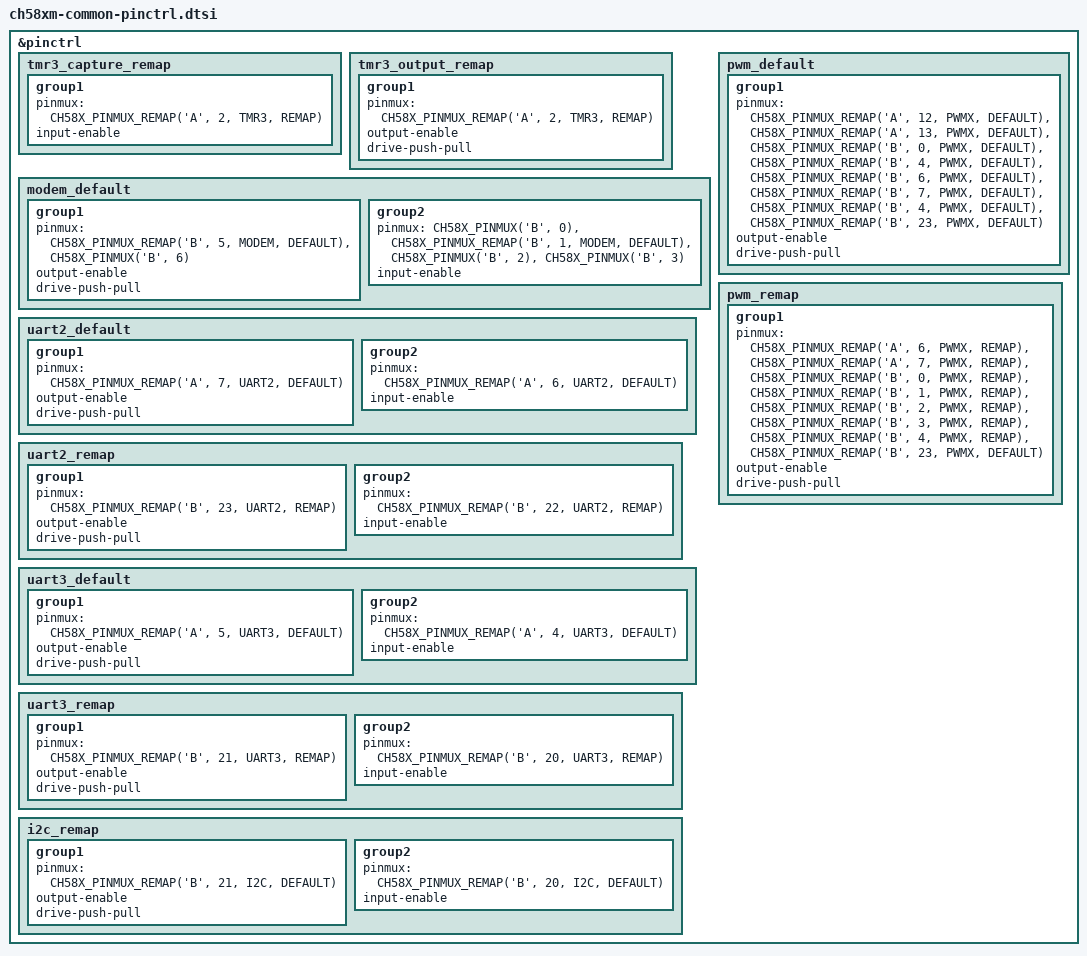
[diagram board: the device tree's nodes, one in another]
/*
 * Copyright (c) 2023-2024 Chen Xingyu <hi@xingrz.me>
 * SPDX-License-Identifier: Apache-2.0
 */

#include <zephyr/dt-bindings/pinctrl/ch58x-pinctrl.h>

&pinctrl {
	/omit-if-no-ref/ tmr3_capture_remap: tmr3_capture_remap {
		group1 {
			pinmux = <CH58X_PINMUX_REMAP('A', 2, TMR3, REMAP)>; /* TMR3_ */
			input-enable;
		};
	};

	/omit-if-no-ref/ tmr3_output_remap: tmr3_output_remap {
		group1 {
			pinmux = <CH58X_PINMUX_REMAP('A', 2, TMR3, REMAP)>; /* TMR3_ */
			output-enable;
			drive-push-pull;
		};
	};

	/omit-if-no-ref/ modem_default: modem_default {
		group1 {
			pinmux = <CH58X_PINMUX_REMAP('B', 5, MODEM, DEFAULT)>, /* DTR */
				 <CH58X_PINMUX('B', 6)>;  /* RTS */
			output-enable;
			drive-push-pull;
		};
		group2 {
			pinmux = <CH58X_PINMUX('B', 0)>,  /* CTS */
				 <CH58X_PINMUX_REMAP('B', 1, MODEM, DEFAULT)>, /* DSR */
				 <CH58X_PINMUX('B', 2)>,  /* RI */
				 <CH58X_PINMUX('B', 3)>;  /* DCD */
			input-enable;
		};
	};

	/omit-if-no-ref/ uart2_default: uart2_default {
		group1 {
			pinmux = <CH58X_PINMUX_REMAP('A', 7, UART2, DEFAULT)>; /* TXD2 */
			output-enable;
			drive-push-pull;
		};
		group2 {
			pinmux = <CH58X_PINMUX_REMAP('A', 6, UART2, DEFAULT)>; /* RXD2 */
			input-enable;
		};
	};

	/omit-if-no-ref/ uart2_remap: uart2_remap {
		group1 {
			pinmux = <CH58X_PINMUX_REMAP('B', 23, UART2, REMAP)>; /* TXD2_ */
			output-enable;
			drive-push-pull;
		};
		group2 {
			pinmux = <CH58X_PINMUX_REMAP('B', 22, UART2, REMAP)>; /* RXD2_ */
			input-enable;
		};
	};

	/omit-if-no-ref/ uart3_default: uart3_default {
		group1 {
			pinmux = <CH58X_PINMUX_REMAP('A', 5, UART3, DEFAULT)>; /* TXD3 */
			output-enable;
			drive-push-pull;
		};
		group2 {
			pinmux = <CH58X_PINMUX_REMAP('A', 4, UART3, DEFAULT)>; /* RXD3 */
			input-enable;
		};
	};

	/omit-if-no-ref/ uart3_remap: uart3_remap {
		group1 {
			pinmux = <CH58X_PINMUX_REMAP('B', 21, UART3, REMAP)>; /* TXD3_ */
			output-enable;
			drive-push-pull;
		};
		group2 {
			pinmux = <CH58X_PINMUX_REMAP('B', 20, UART3, REMAP)>; /* RXD3_ */
			input-enable;
		};
	};

	/omit-if-no-ref/ i2c_remap: i2c_remap {
		group1 {
			pinmux = <CH58X_PINMUX_REMAP('B', 21, I2C, DEFAULT)>; /* SCL_ */
			output-enable;
			drive-push-pull;
		};
		group2 {
			pinmux = <CH58X_PINMUX_REMAP('B', 20, I2C, DEFAULT)>; /* SDA_ */
			input-enable;
		};
	};

	/omit-if-no-ref/ pwm_default: pwm_default {
		group1 {
			pinmux = <CH58X_PINMUX_REMAP('A', 12, PWMX, DEFAULT)>, /*PWM4*/
				<CH58X_PINMUX_REMAP('A', 13, PWMX, DEFAULT)>, /*PWM5*/
				<CH58X_PINMUX_REMAP('B', 0, PWMX, DEFAULT)>, /*PWM6*/
				<CH58X_PINMUX_REMAP('B', 4, PWMX, DEFAULT)>, /*PWM7*/
				<CH58X_PINMUX_REMAP('B', 6, PWMX, DEFAULT)>, /*PWM8*/
				<CH58X_PINMUX_REMAP('B', 7, PWMX, DEFAULT)>, /*PWM9*/
				<CH58X_PINMUX_REMAP('B', 4, PWMX, DEFAULT)>, /*PWM10*/
				<CH58X_PINMUX_REMAP('B', 23, PWMX, DEFAULT)>; /*PWM11*/
			output-enable;
			drive-push-pull;
		};
	};
	
	/omit-if-no-ref/ pwm_remap: pwm_remap {
		group1 {
			pinmux = <CH58X_PINMUX_REMAP('A', 6, PWMX, REMAP)>, /*PWM4*/
				<CH58X_PINMUX_REMAP('A', 7, PWMX, REMAP)>, /*PWM5*/
				<CH58X_PINMUX_REMAP('B', 0, PWMX, REMAP)>, /*PWM6, no remap available*/
				<CH58X_PINMUX_REMAP('B', 1, PWMX, REMAP)>, /*PWM7*/
				<CH58X_PINMUX_REMAP('B', 2, PWMX, REMAP)>, /*PWM8*/
				<CH58X_PINMUX_REMAP('B', 3, PWMX, REMAP)>, /*PWM9*/
				<CH58X_PINMUX_REMAP('B', 4, PWMX, REMAP)>, /*PWM10, no remap available*/
				<CH58X_PINMUX_REMAP('B', 23, PWMX, DEFAULT)>; /*PWM11, no remap available*/
			output-enable;
			drive-push-pull;
		};
	};

};
